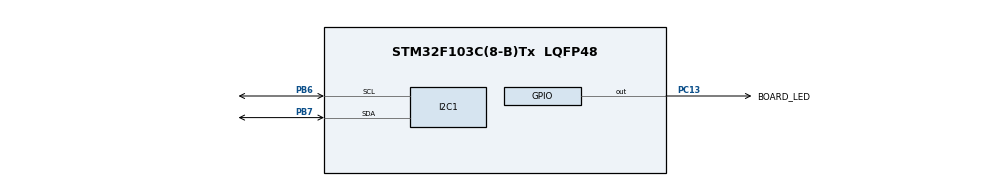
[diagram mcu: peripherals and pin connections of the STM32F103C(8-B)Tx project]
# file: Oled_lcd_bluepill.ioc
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Mcu.Family=STM32F1
Mcu.Name=STM32F103C(8-B)Tx
Mcu.Package=LQFP48
NVIC.PriorityGroup=NVIC_PRIORITYGROUP_4
PB6.Mode=I2C
PB6.Signal=I2C1_SCL
PB7.Mode=I2C
PB7.Signal=I2C1_SDA
PC13-TAMPER-RTC.GPIO_Label=BOARD_LED
PC13-TAMPER-RTC.Signal=GPIO_Output
ProjectManager.HeapSize=0x200
ProjectManager.StackSize=0x400
ProjectManager.TargetToolchain=STM32CubeIDE
RCC.APB1Freq_Value=8000000
RCC.APB2Freq_Value=8000000
board=custom

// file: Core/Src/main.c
/* USER CODE BEGIN Header */
/**
  ******************************************************************************
  * @file           : main.c
  * @brief          : Main program body
  ******************************************************************************
  * @attention
  *
  * Copyright (c) 2023 STMicroelectronics.
  * All rights reserved.
  *
  * This software is licensed under terms that can be found in the LICENSE file
  * in the root directory of this software component.
  * If no LICENSE file comes with this software, it is provided AS-IS.
  *
  ******************************************************************************
  */
/* USER CODE END Header */
#include "main.h"

I2C_HandleTypeDef hi2c1;

void SystemClock_Config(void);
static void MX_GPIO_Init(void);
static void MX_I2C1_Init(void);

/* USER CODE BEGIN 0 */
void delay(int n);
/* USER CODE END 0 */

int main(void)
{
  /* USER CODE BEGIN 1 */
	char message[] = "EA";
	char message1[] = "Works!!";
	char numbers[] = "0123456789";
	char cresponse = '\0';
	char currentchar = '\0';
	int i = 0;
  /* USER CODE END 1 */

  /* MCU Configuration--------------------------------------------------------*/

  /* Reset of all peripherals, Initializes the Flash interface and the Systick. */
  HAL_Init();

  /* Configure the system clock */
  SystemClock_Config();

  /* Initialize all configured peripherals */
  MX_GPIO_Init();
  MX_I2C1_Init();
  /* USER CODE BEGIN 2 */

  ssd1306_Init();
  HAL_GPIO_WritePin(BOARD_LED_GPIO_Port, BOARD_LED_Pin, GPIO_PIN_SET);

  /* USER CODE END 2 */

  /* Infinite loop */
  while (1)
  {

    /* USER CODE BEGIN 3 */
	  if(i == 10) {
		  i = 0;
	  }
	  currentchar = numbers[i];
	  ssd1306_Fill(Black);
	  ssd1306_UpdateScreen();
	  ssd1306_SetCursor(5,5);
	  cresponse = ssd1306_WriteString(message, Font_6x8, White);
	  if(cresponse == '\0'){
		  ssd1306_UpdateScreen();
	  }
	  ssd1306_SetCursor(5,20);
	  cresponse = ssd1306_WriteString(message1, Font_7x10, White);
	  if(cresponse == '\0'){
		  ssd1306_UpdateScreen();
	  }
	  cresponse = ssd1306_WriteChar(currentchar, Font_7x10, White);
	  if(cresponse == '\0'){
		  ssd1306_UpdateScreen();
	  }
	  i++;
	  HAL_GPIO_TogglePin(BOARD_LED_GPIO_Port, BOARD_LED_Pin);
	  delay(50000);
  }
  /* USER CODE END 3 */
}

void SystemClock_Config(void)
{
  RCC_OscInitTypeDef RCC_OscInitStruct = {0};
  RCC_ClkInitTypeDef RCC_ClkInitStruct = {0};

  /** Initializes the RCC Oscillators according to the specified parameters
  * in the RCC_OscInitTypeDef structure.
  */
  RCC_OscInitStruct.OscillatorType = RCC_OSCILLATORTYPE_HSI;
  RCC_OscInitStruct.HSIState = RCC_HSI_ON;
  RCC_OscInitStruct.HSICalibrationValue = RCC_HSICALIBRATION_DEFAULT;
  RCC_OscInitStruct.PLL.PLLState = RCC_PLL_NONE;
  if (HAL_RCC_OscConfig(&RCC_OscInitStruct) != HAL_OK)
  {
    Error_Handler();
  }

  /** Initializes the CPU, AHB and APB buses clocks
  */
  RCC_ClkInitStruct.ClockType = RCC_CLOCKTYPE_HCLK|RCC_CLOCKTYPE_SYSCLK
                              |RCC_CLOCKTYPE_PCLK1|RCC_CLOCKTYPE_PCLK2;
  RCC_ClkInitStruct.SYSCLKSource = RCC_SYSCLKSOURCE_HSI;
  RCC_ClkInitStruct.AHBCLKDivider = RCC_SYSCLK_DIV1;
  RCC_ClkInitStruct.APB1CLKDivider = RCC_HCLK_DIV1;
  RCC_ClkInitStruct.APB2CLKDivider = RCC_HCLK_DIV1;

  if (HAL_RCC_ClockConfig(&RCC_ClkInitStruct, FLASH_LATENCY_0) != HAL_OK)
  {
    Error_Handler();
  }
}

static void MX_I2C1_Init(void)
{

  hi2c1.Instance = I2C1;
  hi2c1.Init.ClockSpeed = 100000;
  hi2c1.Init.DutyCycle = I2C_DUTYCYCLE_2;
  hi2c1.Init.OwnAddress1 = 0;
  hi2c1.Init.AddressingMode = I2C_ADDRESSINGMODE_7BIT;
  hi2c1.Init.DualAddressMode = I2C_DUALADDRESS_DISABLE;
  hi2c1.Init.OwnAddress2 = 0;
  hi2c1.Init.GeneralCallMode = I2C_GENERALCALL_DISABLE;
  hi2c1.Init.NoStretchMode = I2C_NOSTRETCH_DISABLE;
  if (HAL_I2C_Init(&hi2c1) != HAL_OK)
  {
    Error_Handler();
  }

}

static void MX_GPIO_Init(void)
{
  GPIO_InitTypeDef GPIO_InitStruct = {0};

  /* GPIO Ports Clock Enable */
  __HAL_RCC_GPIOC_CLK_ENABLE();
  __HAL_RCC_GPIOB_CLK_ENABLE();

  /*Configure GPIO pin Output Level */
  HAL_GPIO_WritePin(BOARD_LED_GPIO_Port, BOARD_LED_Pin, GPIO_PIN_RESET);

  /*Configure GPIO pin : BOARD_LED_Pin */
  GPIO_InitStruct.Pin = BOARD_LED_Pin;
  GPIO_InitStruct.Mode = GPIO_MODE_OUTPUT_PP;
  GPIO_InitStruct.Pull = GPIO_NOPULL;
  GPIO_InitStruct.Speed = GPIO_SPEED_FREQ_LOW;
  HAL_GPIO_Init(BOARD_LED_GPIO_Port, &GPIO_InitStruct);

}

/* USER CODE BEGIN 4 */
void delay(int n){
	int i,j;
	j = 0;
	for(i = 0; i < n; i++){
		j++;
	}
}
/* USER CODE END 4 */

void Error_Handler(void)
{
  __disable_irq();
  while (1)
  {
  }
}
